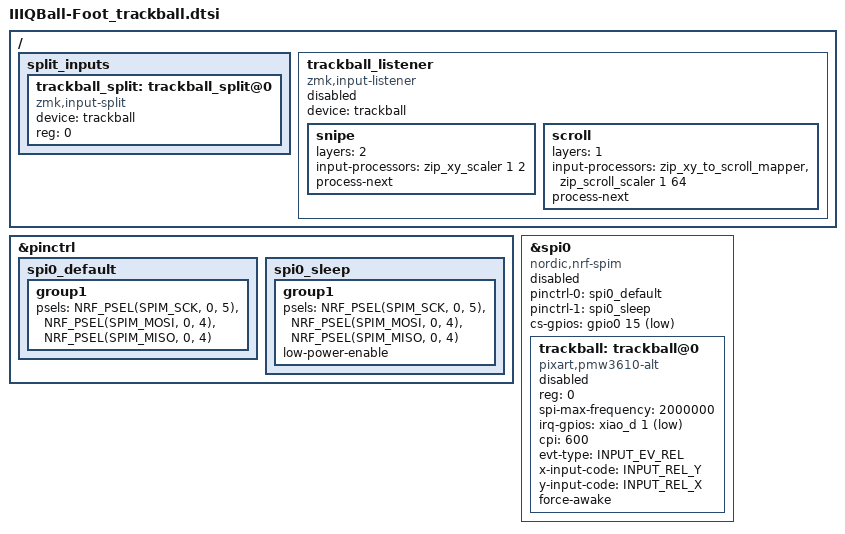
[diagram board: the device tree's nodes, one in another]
#include <zephyr/dt-bindings/input/input-event-codes.h>
#include <input/processors.dtsi>

&pinctrl {
    spi0_default: spi0_default {
        group1 {
            psels = <NRF_PSEL(SPIM_SCK, 0, 5)>,
                    <NRF_PSEL(SPIM_MOSI, 0, 4)>,
                    <NRF_PSEL(SPIM_MISO, 0, 4)>;
        };
    };
    spi0_sleep: spi0_sleep {
        group1 {
            psels = <NRF_PSEL(SPIM_SCK, 0, 5)>,
                    <NRF_PSEL(SPIM_MOSI, 0, 4)>,
                    <NRF_PSEL(SPIM_MISO, 0, 4)>;
            low-power-enable;
        };
    };
};

&spi0 {
    status = "disabled";
    compatible = "nordic,nrf-spim";
    pinctrl-0 = <&spi0_default>;
    pinctrl-1 = <&spi0_sleep>;
    pinctrl-names = "default", "sleep";
    cs-gpios = <&gpio0 15 GPIO_ACTIVE_LOW>;

    trackball: trackball@0 {
        status = "disabled";
        compatible = "pixart,pmw3610-alt";
        reg = <0>;
        spi-max-frequency = <2000000>;
        irq-gpios = <&xiao_d 1 (GPIO_ACTIVE_LOW | GPIO_PULL_UP)>;
        cpi = <600>;
        evt-type = <INPUT_EV_REL>;
        x-input-code = <INPUT_REL_Y>; 
        y-input-code = <INPUT_REL_X>;
        force-awake;

    };
};

/ {
    split_inputs {
        #address-cells = <1>;
        #size-cells = <0>;

        trackball_split: trackball_split@0 {
            device = <&trackball>;
            compatible = "zmk,input-split";
            reg = <0>;
        };
    };

    trackball_listener: trackball_listener {
        compatible = "zmk,input-listener";
        status = "disabled";
        device = <&trackball>;

        snipe {
        layers = <2>;
        input-processors = <&zip_xy_scaler 1 2>;
        process-next;
        };

        scroll {
        layers = <1>;
        input-processors = <&zip_xy_to_scroll_mapper>, <&zip_scroll_scaler 1 64>;
        process-next;
        };

    };
};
